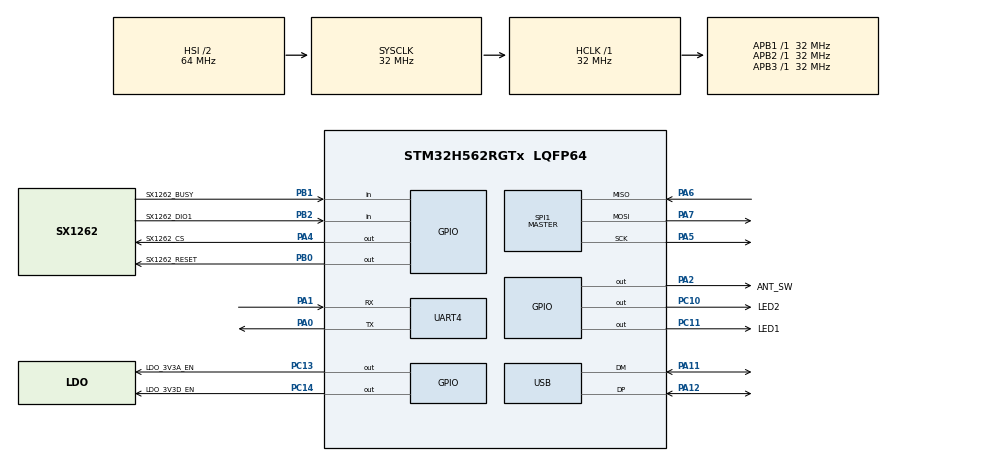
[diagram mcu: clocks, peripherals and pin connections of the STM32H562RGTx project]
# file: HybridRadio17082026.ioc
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BOOTPATH.BootPathName=LEGACY
BOOTPATH.UserSelectedBootPath=LEGACY
CORTEX_M33_NS.Number-Cortex_Memory_Protection_Unit_Region0_OTP_RO_AREAS_Settings=MPU_REGION_NUMBER0
CORTEX_M33_NS.default_mode_Activation=1
CORTEX_M33_NS.userName=CORTEX_M33
Mcu.Family=STM32H5
Mcu.Name=STM32H562RGTx
Mcu.Package=LQFP64
NVIC.PriorityGroup=NVIC_PRIORITYGROUP_4
PA0.Mode=Asynchronous
PA0.Signal=UART4_TX
PA1.Mode=Asynchronous
PA1.Signal=UART4_RX
PA11.Mode=Device
PA11.Signal=USB_DM
PA12.Mode=Device
PA12.Signal=USB_DP
PA2.GPIO_Label=ANT_SW
PA2.Signal=GPIO_Output
PA4.GPIO_Label=SX1262_CS
PA4.Signal=GPIO_Output
PA5.Mode=Full_Duplex_Master
PA5.Signal=SPI1_SCK
PA6.Mode=Full_Duplex_Master
PA6.Signal=SPI1_MISO
PA7.Mode=Full_Duplex_Master
PA7.Signal=SPI1_MOSI
PB0.GPIO_Label=SX1262_RESET
PB0.Signal=GPIO_Output
PB1.GPIO_Label=SX1262_BUSY
PB1.Signal=GPIO_Input
PB2.GPIO_Label=SX1262_DIO1
PB2.Signal=GPIO_Input
PC10.GPIO_Label=LED2
PC10.Signal=GPIO_Output
PC11.GPIO_Label=LED1
PC11.Signal=GPIO_Output
PC13.GPIO_Label=LDO_3V3A_EN
PC13.Signal=GPIO_Output
PC14-OSC32_IN(OSC32_IN).GPIO_Label=LDO_3V3D_EN
PC14-OSC32_IN(OSC32_IN).Signal=GPIO_Output
PH0-OSC_IN(PH0).Mode=HSE-External-Oscillator
PH0-OSC_IN(PH0).Signal=RCC_OSC_IN
PH1-OSC_OUT(PH1).Mode=HSE-External-Oscillator
PH1-OSC_OUT(PH1).Signal=RCC_OSC_OUT
ProjectManager.HeapSize=0x200
ProjectManager.StackSize=0x400
ProjectManager.TargetToolchain=CMake
RCC.ADCFreq_Value=32000000
RCC.AHBFreq_Value=32000000
RCC.APB1Freq_Value=32000000
RCC.APB1TimFreq_Value=32000000
RCC.APB2Freq_Value=32000000
RCC.APB2TimFreq_Value=32000000
RCC.APB3Freq_Value=32000000
RCC.CSI_VALUE=4000000
RCC.CortexFreq_Value=32000000
RCC.EPOD_VALUE=4000000
RCC.HCLKFreq_Value=32000000
RCC.HSE_VALUE=12000000
RCC.HSI48_VALUE=48000000
RCC.HSI_VALUE=64000000
RCC.LSE_VALUE=32768
RCC.LSIRC_VALUE=32000
RCC.PLL1Q=3
RCC.PLLFRACN=0
RCC.PLLN=32
RCC.SYSCLKFreq_VALUE=32000000
RCC.USBFreq_Value=48000000
RCC.VCOOutputFreq_Value=128000000
SPI1.BaudRatePrescaler=SPI_BAUDRATEPRESCALER_4
SPI1.CalculateBaudRate=10.666666 MBits/s
SPI1.DataSize=SPI_DATASIZE_8BIT
SPI1.Direction=SPI_DIRECTION_2LINES
SPI1.Mode=SPI_MODE_MASTER
SPI1.VirtualType=VM_MASTER
USB.VirtualMode=Device_Only
VP_BOOTPATH_VS_BOOTPATH.Mode=BP_Activate
VP_CORTEX_M33_NS_VS_Hclk.Mode=Hclk_Mode
VP_ICACHE_VS_ICACHE.Mode=DirectMappedCache
VP_MEMORYMAP_VS_MEMORYMAP.Mode=CurAppReg
VP_PWR_VS_LPOM.Mode=PowerOptimisation
VP_PWR_VS_SECSignals.Mode=Security/Privilege
board=custom

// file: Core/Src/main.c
/* USER CODE BEGIN Header */
/**
  ******************************************************************************
  * @file           : main.c
  * @brief          : Main program body
  ******************************************************************************
  * @attention
  *
  * Copyright (c) 2026 STMicroelectronics.
  * All rights reserved.
  *
  * This software is licensed under terms that can be found in the LICENSE file
  * in the root directory of this software component.
  * If no LICENSE file comes with this software, it is provided AS-IS.
  *
  ******************************************************************************
  */
/* USER CODE END Header */
#include "main.h"

/* USER CODE BEGIN Includes */
#include "radio.h"
/* USER CODE END Includes */

SPI_HandleTypeDef hspi1;

UART_HandleTypeDef huart4;

PCD_HandleTypeDef hpcd_USB_DRD_FS;

void SystemClock_Config(void);
static void MPU_Config(void);
static void MX_GPIO_Init(void);
static void MX_ICACHE_Init(void);
static void MX_UART4_Init(void);
static void MX_SPI1_Init(void);
static void MX_USB_PCD_Init(void);

int main(void)
{

  /* MCU Configuration--------------------------------------------------------*/

  /* MPU Configuration--------------------------------------------------------*/
  MPU_Config();

  /* Reset of all peripherals, Initializes the Flash interface and the Systick. */
  HAL_Init();

  /* Configure the system clock */
  SystemClock_Config();

  /* Initialize all configured peripherals */
  MX_GPIO_Init();
  MX_ICACHE_Init();
  MX_UART4_Init();
  MX_SPI1_Init();
  MX_USB_PCD_Init();
  /* USER CODE BEGIN 2 */
  /* Radio disabled for LED-only bring-up test -- re-enable once LED1 is confirmed good.
  Radio_PowerOn();

  const uint8_t msg[] = "Hello from H562";
  */
  /* USER CODE END 2 */

  /* Infinite loop */
  while (1)
  {
    /* USER CODE BEGIN 3 */
    /* Radio disabled for LED-only bring-up test -- re-enable once LED1 is confirmed good.
    if (SX1262_SendPacket(msg, sizeof(msg) - 1) == HAL_OK)
    {
        // TxDone confirmed
        HAL_GPIO_TogglePin(LED1_GPIO_Port, LED1_Pin);
    }
    */
    HAL_GPIO_TogglePin(LED1_GPIO_Port, LED1_Pin);
    HAL_Delay(500);
  }
  /* USER CODE END 3 */
}

void SystemClock_Config(void)
{
  RCC_OscInitTypeDef RCC_OscInitStruct = {0};
  RCC_ClkInitTypeDef RCC_ClkInitStruct = {0};

  /** Configure the main internal regulator output voltage
  */
  __HAL_PWR_VOLTAGESCALING_CONFIG(PWR_REGULATOR_VOLTAGE_SCALE3);

  while(!__HAL_PWR_GET_FLAG(PWR_FLAG_VOSRDY)) {}

  /** Initializes the RCC Oscillators according to the specified parameters
  * in the RCC_OscInitTypeDef structure.
  */
  RCC_OscInitStruct.OscillatorType = RCC_OSCILLATORTYPE_HSI48|RCC_OSCILLATORTYPE_HSI
                              |RCC_OSCILLATORTYPE_CSI;
  RCC_OscInitStruct.HSIState = RCC_HSI_ON;
  RCC_OscInitStruct.HSIDiv = RCC_HSI_DIV2;
  RCC_OscInitStruct.HSICalibrationValue = RCC_HSICALIBRATION_DEFAULT;
  RCC_OscInitStruct.HSI48State = RCC_HSI48_ON;
  RCC_OscInitStruct.CSIState = RCC_CSI_ON;
  RCC_OscInitStruct.CSICalibrationValue = RCC_CSICALIBRATION_DEFAULT;
  RCC_OscInitStruct.PLL.PLLState = RCC_PLL_ON;
  RCC_OscInitStruct.PLL.PLLSource = RCC_PLL1_SOURCE_CSI;
  RCC_OscInitStruct.PLL.PLLM = 1;
  RCC_OscInitStruct.PLL.PLLN = 32;
  RCC_OscInitStruct.PLL.PLLP = 2;
  RCC_OscInitStruct.PLL.PLLQ = 3;
  RCC_OscInitStruct.PLL.PLLR = 2;
  RCC_OscInitStruct.PLL.PLLRGE = RCC_PLL1_VCIRANGE_2;
  RCC_OscInitStruct.PLL.PLLVCOSEL = RCC_PLL1_VCORANGE_WIDE;
  RCC_OscInitStruct.PLL.PLLFRACN = 0;
  if (HAL_RCC_OscConfig(&RCC_OscInitStruct) != HAL_OK)
  {
    Error_Handler();
  }

  /** Initializes the CPU, AHB and APB buses clocks
  */
  RCC_ClkInitStruct.ClockType = RCC_CLOCKTYPE_HCLK|RCC_CLOCKTYPE_SYSCLK
                              |RCC_CLOCKTYPE_PCLK1|RCC_CLOCKTYPE_PCLK2
                              |RCC_CLOCKTYPE_PCLK3;
  RCC_ClkInitStruct.SYSCLKSource = RCC_SYSCLKSOURCE_HSI;
  RCC_ClkInitStruct.AHBCLKDivider = RCC_SYSCLK_DIV1;
  RCC_ClkInitStruct.APB1CLKDivider = RCC_HCLK_DIV1;
  RCC_ClkInitStruct.APB2CLKDivider = RCC_HCLK_DIV1;
  RCC_ClkInitStruct.APB3CLKDivider = RCC_HCLK_DIV1;

  if (HAL_RCC_ClockConfig(&RCC_ClkInitStruct, FLASH_LATENCY_1) != HAL_OK)
  {
    Error_Handler();
  }

  /** Configure the programming delay
  */
  __HAL_FLASH_SET_PROGRAM_DELAY(FLASH_PROGRAMMING_DELAY_0);
}

static void MX_ICACHE_Init(void)
{

  /** Enable instruction cache in 1-way (direct mapped cache)
  */
  if (HAL_ICACHE_ConfigAssociativityMode(ICACHE_1WAY) != HAL_OK)
  {
    Error_Handler();
  }
  if (HAL_ICACHE_Enable() != HAL_OK)
  {
    Error_Handler();
  }

}

static void MX_SPI1_Init(void)
{

  /* SPI1 parameter configuration*/
  hspi1.Instance = SPI1;
  hspi1.Init.Mode = SPI_MODE_MASTER;
  hspi1.Init.Direction = SPI_DIRECTION_2LINES;
  hspi1.Init.DataSize = SPI_DATASIZE_8BIT;
  hspi1.Init.CLKPolarity = SPI_POLARITY_LOW;
  hspi1.Init.CLKPhase = SPI_PHASE_1EDGE;
  hspi1.Init.NSS = SPI_NSS_SOFT;
  hspi1.Init.BaudRatePrescaler = SPI_BAUDRATEPRESCALER_4;
  hspi1.Init.FirstBit = SPI_FIRSTBIT_MSB;
  hspi1.Init.TIMode = SPI_TIMODE_DISABLE;
  hspi1.Init.CRCCalculation = SPI_CRCCALCULATION_DISABLE;
  hspi1.Init.CRCPolynomial = 0x7;
  hspi1.Init.NSSPMode = SPI_NSS_PULSE_ENABLE;
  hspi1.Init.NSSPolarity = SPI_NSS_POLARITY_LOW;
  hspi1.Init.FifoThreshold = SPI_FIFO_THRESHOLD_01DATA;
  hspi1.Init.MasterSSIdleness = SPI_MASTER_SS_IDLENESS_00CYCLE;
  hspi1.Init.MasterInterDataIdleness = SPI_MASTER_INTERDATA_IDLENESS_00CYCLE;
  hspi1.Init.MasterReceiverAutoSusp = SPI_MASTER_RX_AUTOSUSP_DISABLE;
  hspi1.Init.MasterKeepIOState = SPI_MASTER_KEEP_IO_STATE_DISABLE;
  hspi1.Init.IOSwap = SPI_IO_SWAP_DISABLE;
  hspi1.Init.ReadyMasterManagement = SPI_RDY_MASTER_MANAGEMENT_INTERNALLY;
  hspi1.Init.ReadyPolarity = SPI_RDY_POLARITY_HIGH;
  if (HAL_SPI_Init(&hspi1) != HAL_OK)
  {
    Error_Handler();
  }

}

static void MX_UART4_Init(void)
{

  huart4.Instance = UART4;
  huart4.Init.BaudRate = 115200;
  huart4.Init.WordLength = UART_WORDLENGTH_8B;
  huart4.Init.StopBits = UART_STOPBITS_1;
  huart4.Init.Parity = UART_PARITY_NONE;
  huart4.Init.Mode = UART_MODE_TX_RX;
  huart4.Init.HwFlowCtl = UART_HWCONTROL_NONE;
  huart4.Init.OverSampling = UART_OVERSAMPLING_16;
  huart4.Init.OneBitSampling = UART_ONE_BIT_SAMPLE_DISABLE;
  huart4.Init.ClockPrescaler = UART_PRESCALER_DIV1;
  huart4.AdvancedInit.AdvFeatureInit = UART_ADVFEATURE_NO_INIT;
  if (HAL_UART_Init(&huart4) != HAL_OK)
  {
    Error_Handler();
  }
  if (HAL_UARTEx_SetTxFifoThreshold(&huart4, UART_TXFIFO_THRESHOLD_1_8) != HAL_OK)
  {
    Error_Handler();
  }
  if (HAL_UARTEx_SetRxFifoThreshold(&huart4, UART_RXFIFO_THRESHOLD_1_8) != HAL_OK)
  {
    Error_Handler();
  }
  if (HAL_UARTEx_DisableFifoMode(&huart4) != HAL_OK)
  {
    Error_Handler();
  }

}

static void MX_USB_PCD_Init(void)
{

  hpcd_USB_DRD_FS.Instance = USB_DRD_FS;
  hpcd_USB_DRD_FS.Init.dev_endpoints = 8;
  hpcd_USB_DRD_FS.Init.speed = USBD_FS_SPEED;
  hpcd_USB_DRD_FS.Init.phy_itface = PCD_PHY_EMBEDDED;
  hpcd_USB_DRD_FS.Init.Sof_enable = DISABLE;
  hpcd_USB_DRD_FS.Init.low_power_enable = DISABLE;
  hpcd_USB_DRD_FS.Init.lpm_enable = DISABLE;
  hpcd_USB_DRD_FS.Init.battery_charging_enable = DISABLE;
  hpcd_USB_DRD_FS.Init.vbus_sensing_enable = DISABLE;
  hpcd_USB_DRD_FS.Init.bulk_doublebuffer_enable = DISABLE;
  hpcd_USB_DRD_FS.Init.iso_singlebuffer_enable = DISABLE;
  if (HAL_PCD_Init(&hpcd_USB_DRD_FS) != HAL_OK)
  {
    Error_Handler();
  }

}

static void MX_GPIO_Init(void)
{
  GPIO_InitTypeDef GPIO_InitStruct = {0};

  /* GPIO Ports Clock Enable */
  __HAL_RCC_GPIOC_CLK_ENABLE();
  __HAL_RCC_GPIOH_CLK_ENABLE();
  __HAL_RCC_GPIOA_CLK_ENABLE();
  __HAL_RCC_GPIOB_CLK_ENABLE();

  /*Configure GPIO pin Output Level */
  HAL_GPIO_WritePin(GPIOC, LDO_3V3A_EN_Pin|LDO_3V3D_EN_Pin|LED2_Pin|LED1_Pin, GPIO_PIN_RESET);

  /*Configure GPIO pin Output Level */
  HAL_GPIO_WritePin(GPIOA, ANT_SW_Pin|SX1262_CS_Pin, GPIO_PIN_RESET);

  /*Configure GPIO pin Output Level */
  HAL_GPIO_WritePin(SX1262_RESET_GPIO_Port, SX1262_RESET_Pin, GPIO_PIN_RESET);

  /*Configure GPIO pins : LDO_3V3A_EN_Pin LDO_3V3D_EN_Pin LED2_Pin LED1_Pin */
  GPIO_InitStruct.Pin = LDO_3V3A_EN_Pin|LDO_3V3D_EN_Pin|LED2_Pin|LED1_Pin;
  GPIO_InitStruct.Mode = GPIO_MODE_OUTPUT_PP;
  GPIO_InitStruct.Pull = GPIO_NOPULL;
  GPIO_InitStruct.Speed = GPIO_SPEED_FREQ_LOW;
  HAL_GPIO_Init(GPIOC, &GPIO_InitStruct);

  /*Configure GPIO pins : ANT_SW_Pin SX1262_CS_Pin */
  GPIO_InitStruct.Pin = ANT_SW_Pin|SX1262_CS_Pin;
  GPIO_InitStruct.Mode = GPIO_MODE_OUTPUT_PP;
  GPIO_InitStruct.Pull = GPIO_NOPULL;
  GPIO_InitStruct.Speed = GPIO_SPEED_FREQ_LOW;
  HAL_GPIO_Init(GPIOA, &GPIO_InitStruct);

  /*Configure GPIO pin : SX1262_RESET_Pin */
  GPIO_InitStruct.Pin = SX1262_RESET_Pin;
  GPIO_InitStruct.Mode = GPIO_MODE_OUTPUT_PP;
  GPIO_InitStruct.Pull = GPIO_NOPULL;
  GPIO_InitStruct.Speed = GPIO_SPEED_FREQ_LOW;
  HAL_GPIO_Init(SX1262_RESET_GPIO_Port, &GPIO_InitStruct);

  /*Configure GPIO pins : SX1262_BUSY_Pin SX1262_DIO1_Pin */
  GPIO_InitStruct.Pin = SX1262_BUSY_Pin|SX1262_DIO1_Pin;
  GPIO_InitStruct.Mode = GPIO_MODE_INPUT;
  GPIO_InitStruct.Pull = GPIO_NOPULL;
  HAL_GPIO_Init(GPIOB, &GPIO_InitStruct);

}

 /* MPU Configuration */

void MPU_Config(void)
{
  MPU_Region_InitTypeDef MPU_InitStruct = {0};
  MPU_Attributes_InitTypeDef MPU_AttributesInit = {0};

  /* Disables the MPU */
  HAL_MPU_Disable();

  /** Initializes and configures the Region 0 and the memory to be protected
  */
  MPU_InitStruct.Enable = MPU_REGION_ENABLE;
  MPU_InitStruct.Number = MPU_REGION_NUMBER0;
  MPU_InitStruct.BaseAddress = 0x08FFF000;
  MPU_InitStruct.LimitAddress = 0x08FFFFFF;
  MPU_InitStruct.AttributesIndex = MPU_ATTRIBUTES_NUMBER0;
  MPU_InitStruct.AccessPermission = MPU_REGION_ALL_RO;
  MPU_InitStruct.DisableExec = MPU_INSTRUCTION_ACCESS_DISABLE;
  MPU_InitStruct.IsShareable = MPU_ACCESS_NOT_SHAREABLE;

  HAL_MPU_ConfigRegion(&MPU_InitStruct);

  /** Initializes and configures the Attribute 0 and the memory to be protected
  */
  MPU_AttributesInit.Number = MPU_ATTRIBUTES_NUMBER0;
  MPU_AttributesInit.Attributes = INNER_OUTER(MPU_NOT_CACHEABLE);

  HAL_MPU_ConfigMemoryAttributes(&MPU_AttributesInit);
  /* Enables the MPU */
  HAL_MPU_Enable(MPU_PRIVILEGED_DEFAULT);

}

void Error_Handler(void)
{
  __disable_irq();
  while (1)
  {
  }
}
